# ATmega8535 register map
Vendor: Atmel; File version: 1.0
CPU: other r0p0, little endian, no MPU, no FPU, 4 interrupt priority bits
Registers are 8-bit, read-write, reset 0x0 unless marked. A register's access mark holds for its fields unless they carry their own. Offsets are from the block's base; [hi:lo] are bit positions; 'fields as' and 'values as' point back to an identical list.

## EEPROM
Base 0x0000003C
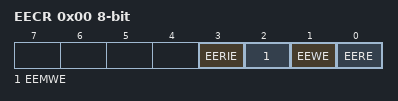
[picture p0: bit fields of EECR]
0x00 EECR — EEPROM Control Register
  [3] EERIE — EEPROM Ready Interrupt Enable
  [2] EEMWE — EEPROM Master Write Enable
  [1] EEWE — EEPROM Write Enable
  [0] EERE — EEPROM Read Enable
0x01 EEDR — EEPROM Data Register
0x02 EEAR 16-bit (reset mask 0xFF) — EEPROM Address Register Bytes

## EXINT — External Interrupts
Base 0x00000054
0x00 MCUCSR — MCU Control And Status Register
  [6] ISC2 — Interrupt Sense Control 2
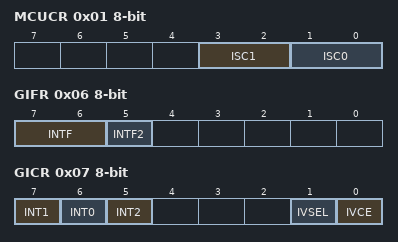
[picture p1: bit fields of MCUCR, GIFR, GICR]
0x01 MCUCR — General Interrupt Control Register
  [3:2] ISC1 — Interrupt Sense Control 1 Bits
    0=Low Level of INTX; 1=Any Logical Change of INTX; 2=Falling Edge of INTX; 3=Rising Edge of INTX
  [1:0] ISC0 — Interrupt Sense Control 0 Bits
    values as ISC1
0x06 GIFR — General Interrupt Flag Register
  [7:6] INTF — External Interrupt Flags
  [5] INTF2 — External Interrupt Flag 2
0x07 GICR — General Interrupt Control Register
  [7] INT1 — External Interrupt Request 1 Enable
  [6] INT0 — External Interrupt Request 0 Enable
  [5] INT2 — External Interrupt Request 2 Enable
  [1] IVSEL — Interrupt Vector Select
  [0] IVCE — Interrupt Vector Change Enable

## LOCKBIT — Lockbits
Base 0x00000000
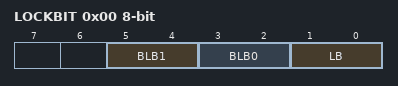
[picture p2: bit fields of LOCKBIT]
0x00 LOCKBIT
  [5:4] BLB1 — Boot Loader Protection Mode
    0=LPM_SPM_DISABLE (LPM and SPM prohibited in Boot Section); 1=LPM_DISABLE (LPM prohibited in Boot Section); 2=SPM_DISABLE (SPM prohibited in Boot Section); 3=NO_LOCK (No lock on SPM and LPM in Boot Section)
  [3:2] BLB0 — Boot Loader Protection Mode
    0=LPM_SPM_DISABLE (LPM and SPM prohibited in Application Section); 1=LPM_DISABLE (LPM prohibited in Application Section); 2=SPM_DISABLE (SPM prohibited in Application Section); 3=NO_LOCK (No lock on SPM and LPM in Application Section)
  [1:0] LB — Memory Lock
    0=PROG_VER_DISABLED (Further programming and verification disabled); 2=PROG_DISABLED (Further programming disabled); 3=NO_LOCK (No memory lock features enabled)

## PORTA — I/O Port
Base 0x00000039
0x00 PINA — Port A Input Pins
0x01 DDRA — Port A Data Direction Register
0x02 PORTA — Port A Data Register

## PORTB — I/O Port
Base 0x00000036
0x00 PINB — Port B Input Pins
0x01 DDRB — Port B Data Direction Register
0x02 PORTB — Port B Data Register

## PORTC — I/O Port
Base 0x00000033
0x00 PINC — Port C Input Pins
0x01 DDRC — Port C Data Direction Register
0x02 PORTC — Port C Data Register

## PORTD — I/O Port
Base 0x00000030
0x00 PIND — Port D Input Pins
0x01 DDRD — Port D Data Direction Register
0x02 PORTD — Port D Data Register

## SPI — Serial Peripheral Interface
Base 0x0000002D
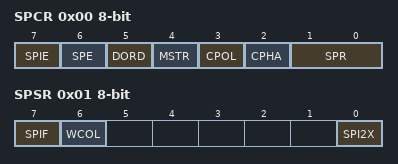
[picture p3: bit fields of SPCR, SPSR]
0x00 SPCR — SPI Control Register
  [7] SPIE — SPI Interrupt Enable
  [6] SPE — SPI Enable
  [5] DORD — Data Order
  [4] MSTR — Master/Slave Select
  [3] CPOL — Clock polarity
  [2] CPHA — Clock Phase
  [1:0] SPR — SPI Clock Rate Selects
    0=fosc/4; 1=fosc/16; 2=fosc/64; 3=fosc/128
0x01 SPSR — SPI Status Register
  [7] SPIF — SPI Interrupt Flag
  [6] WCOL — Write Collision Flag
  [0] SPI2X — Double SPI Speed Bit
0x02 SPDR — SPI Data Register

## TC0 — Timer/Counter, 8-bit
Base 0x00000050
0x00 SFIOR — Special Function IO Register
  [0] PSR10 — Prescaler Reset Timer/Counter1 and Timer/Counter0
0x02 TCNT0 — Timer/Counter Register
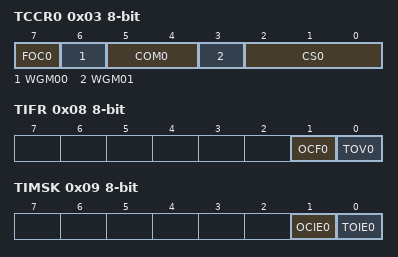
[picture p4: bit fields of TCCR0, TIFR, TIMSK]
0x03 TCCR0 — Timer/Counter Control Register
  [7] FOC0 — Force Output Compare
  [6] WGM00 — Waveform Generation Mode 0
    0=Normal; 1=CTC
  [5:4] COM0 — Compare Match Output Modes
  [3] WGM01 — Waveform Generation Mode 1
  [2:0] CS0 — Clock Selects
    0=No Clock Source (Stopped); 1=Running, No Prescaling; 2=Running, CLK/8; 3=Running, CLK/64; 4=Running, CLK/256; 5=Running, CLK/1024; 6=Running, ExtClk Tx Falling Edge; 7=Running, ExtClk Tx Rising Edge
0x08 TIFR — Timer/Counter Interrupt Flag register
  [1] OCF0 — Output Compare Flag 0
  [0] TOV0 — Timer/Counter0 Overflow Flag
0x09 TIMSK — Timer/Counter Interrupt Mask Register
  [1] OCIE0 — Timer/Counter0 Output Compare Match Interrupt register
  [0] TOIE0 — Timer/Counter0 Overflow Interrupt Enable
0x0C OCR0 — Output Compare Register
